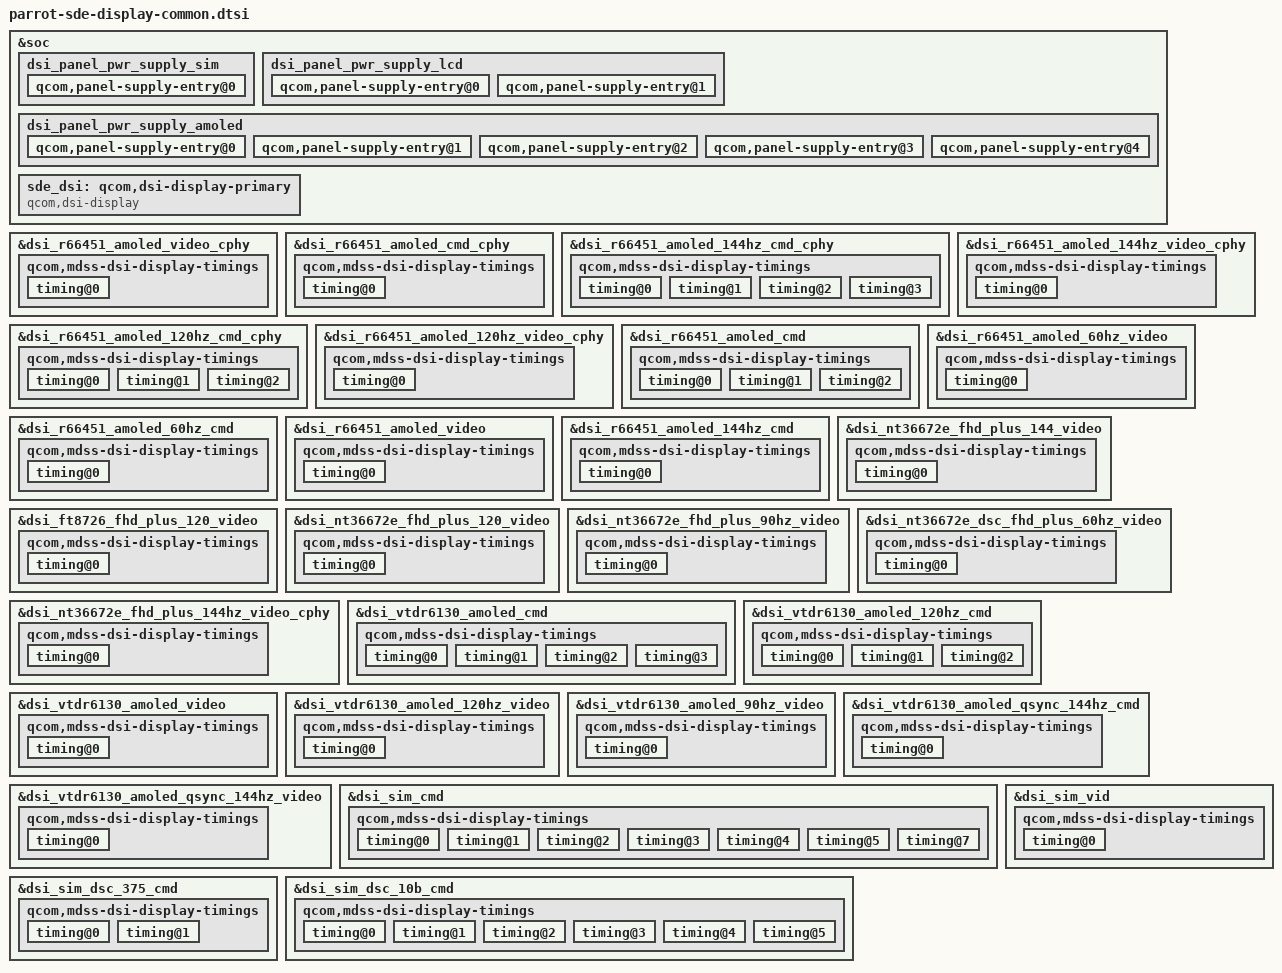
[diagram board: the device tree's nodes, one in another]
#include "dsi-panel-nt36672e-dsc-fhd-plus-60hz-video.dtsi"
#include "dsi-panel-nt36672e-fhd-plus-144-video.dtsi"
#include "dsi-panel-nt36672e-fhd-plus-120-video.dtsi"
#include "dsi-panel-nt36672e-fhd-plus-90hz-video.dtsi"
#include "dsi-panel-nt36672e-fhd-plus-144hz-video-cphy.dtsi"
#include "dsi-panel-sim-cmd.dtsi"
#include "dsi-panel-sim-video.dtsi"
#include "dsi-panel-sim-dsc-10bit-cmd.dtsi"
#include "dsi-panel-sim-dsc375-cmd.dtsi"
#include "dsi-panel-vtdr6130-dsc-fhd-plus-cmd.dtsi"
#include "dsi-panel-vtdr6130-dsc-fhd-plus-video.dtsi"
#include "dsi-panel-vtdr6130-qsync-dsc-fhd-plus-144hz-cmd.dtsi"
#include "dsi-panel-vtdr6130-qsync-dsc-fhd-plus-144hz-video.dtsi"
#include "dsi-panel-r66451-dsc-fhd-plus-cmd.dtsi"
#include "dsi-panel-r66451-dsc-fhd-plus-video.dtsi"
#include "dsi-panel-r66451-dsc-fhd-plus-144hz-cmd-cphy.dtsi"
#include "dsi-panel-r66451-dsc-fhd-plus-144hz-video-cphy.dtsi"
#include "dsi-panel-r66451-dsc-fhd-plus-120hz-cmd-cphy.dtsi"
#include "dsi-panel-r66451-dsc-fhd-plus-cmd-cphy.dtsi"
#include "dsi-panel-r66451-dsc-fhd-plus-60hz-video.dtsi"
#include "dsi-panel-r66451-dsc-fhd-plus-video-cphy.dtsi"
#include "dsi-panel-r66451-dsc-fhd-plus-144hz-cmd.dtsi"
#include "dsi-panel-r66451-dsc-fhd-plus-60hz-cmd.dtsi"
#include "dsi-r66451-amoled-120hz-video-cphy.dtsi"
#include "dsi-panel-vtdr6130-dsc-fhd-plus-120hz-cmd.dtsi"
#include "dsi-panel-vtdr6130-dsc-fhd-plus-120hz-video.dtsi"
#include "dsi-panel-ft8726-dsc-fhd-plus-video.dtsi"
#include "dsi-panel-vtdr6130-dsc-fhd-plus-90hz-video.dtsi"
#include "parrot-sde-display-pinctrl.dtsi"

&soc {
	dsi_panel_pwr_supply_sim: dsi_panel_pwr_supply_sim {
		#address-cells = <1>;
		#size-cells = <0>;

		qcom,panel-supply-entry@0 {
			reg = <0>;
			qcom,supply-name = "dummy";
			qcom,supply-min-voltage = <1800000>;
			qcom,supply-max-voltage = <1800000>;
			qcom,supply-enable-load = <200000>;
			qcom,supply-disable-load = <80>;
			qcom,supply-post-on-sleep = <20>;
		};
	};

	dsi_panel_pwr_supply_lcd: dsi_panel_pwr_supply_lcd {
		#address-cells = <1>;
		#size-cells = <0>;

		qcom,panel-supply-entry@0 {
			reg = <0>;
			qcom,supply-name = "vddio";
			qcom,supply-min-voltage = <1800000>;
			qcom,supply-max-voltage = <2000000>;
			qcom,supply-enable-load = <200000>;
			qcom,supply-disable-load = <80>;
			qcom,supply-post-on-sleep = <10>;
		};

		qcom,panel-supply-entry@1 {
			reg = <1>;
			qcom,supply-name = "avdd";
			qcom,supply-min-voltage = <4600000>;
			qcom,supply-max-voltage = <6000000>;
			qcom,supply-enable-load = <100000>;
			qcom,supply-disable-load = <100>;
			qcom,supply-post-on-sleep = <10>;
			qcom,supply-post-off-sleep = <10>;
		};
	};

	dsi_panel_pwr_supply_amoled: dsi_panel_pwr_supply_amoled {
		#address-cells = <1>;
		#size-cells = <0>;

		qcom,panel-supply-entry@0 {
			reg = <0>;
			qcom,supply-name = "vddio";
			qcom,supply-min-voltage = <1800000>;
			qcom,supply-max-voltage = <2000000>;
			qcom,supply-enable-load = <200000>;
			qcom,supply-disable-load = <80>;
			qcom,supply-post-on-sleep = <20>;
		};

		qcom,panel-supply-entry@1 {
			reg = <1>;
			qcom,supply-name = "vci";
			qcom,supply-min-voltage = <3000000>;
			qcom,supply-max-voltage = <3300000>;
			qcom,supply-enable-load = <10000>;
			qcom,supply-disable-load = <0>;
			qcom,supply-post-on-sleep = <0>;
			qcom,supply-post-off-sleep = <2>;
		};

		qcom,panel-supply-entry@2 {
			reg = <2>;
			qcom,supply-name = "lab";
			qcom,supply-min-voltage = <4600000>;
			qcom,supply-max-voltage = <6000000>;
			qcom,supply-enable-load = <0>;
			qcom,supply-disable-load = <0>;
		};

		qcom,panel-supply-entry@3 {
			reg = <3>;
			qcom,supply-name = "ibb";
			qcom,supply-min-voltage = <4600000>;
			qcom,supply-max-voltage = <6000000>;
			qcom,supply-enable-load = <0>;
			qcom,supply-disable-load = <0>;
			qcom,supply-post-on-sleep = <20>;
		};

		qcom,panel-supply-entry@4 {
			reg = <4>;
			qcom,supply-name = "extvdd";
			qcom,supply-min-voltage = <1200000>;
			qcom,supply-max-voltage = <1200000>;
			qcom,supply-enable-load = <60700>;
			qcom,supply-disable-load = <80>;
			qcom,supply-post-on-sleep = <0>;
			qcom,supply-post-off-sleep = <2>;
		};
	};

	sde_dsi: qcom,dsi-display-primary {
		compatible = "qcom,dsi-display";
		label = "primary";

		qcom,dsi-ctrl = <&mdss_dsi0>;
		qcom,dsi-phy = <&mdss_dsi_phy0>;

		pinctrl-names = "panel_active", "panel_suspend";
		pinctrl-0 = <&sde_dsi_active &sde_te_active>;
		pinctrl-1 = <&sde_dsi_suspend &sde_te_suspend>;

		qcom,platform-te-gpio = <&tlmm 99 0>;
		qcom,panel-te-source = <0>;

		qcom,mdp = <&mdss_mdp>;
		qcom,demura-panel-id = <0x0122e700 0x000000b0>;
	};
};

/* PHY TIMINGS REVISION YL with reduced margins*/
&dsi_r66451_amoled_video_cphy {
	qcom,dsi-select-clocks = "pll_byte_clk0", "pll_dsi_clk0";

	qcom,mdss-dsi-panel-status-check-mode = "reg_read";
	qcom,mdss-dsi-panel-status-command = [06 01 00 01 00 00 01 0a];
	qcom,mdss-dsi-panel-status-command-state = "dsi_lp_mode";
	qcom,mdss-dsi-panel-status-value = <0x1c>;
	qcom,mdss-dsi-panel-status-read-length = <1>;

	qcom,mdss-dsi-display-timings {
		timing@0 {
			qcom,mdss-dsi-panel-phy-timings = [00 00 00 00 12 17 04
				19 03 02 04 00 00 00];
			qcom,display-topology = <1 1 1>;
			qcom,default-topology-index = <0>;
		};
	};
};

&dsi_r66451_amoled_cmd_cphy {
	qcom,dsi-select-clocks = "pll_byte_clk0", "pll_dsi_clk0";

	qcom,esd-check-enabled;
	qcom,mdss-dsi-panel-status-check-mode = "reg_read";
	qcom,mdss-dsi-panel-status-command = [06 01 00 01 00 00 01 0a];
	qcom,mdss-dsi-panel-status-command-state = "dsi_lp_mode";
	qcom,mdss-dsi-panel-status-value = <0x1c>;
	qcom,mdss-dsi-panel-status-read-length = <1>;

	qcom,mdss-dsi-display-timings {
		timing@0 {
			qcom,mdss-dsi-panel-phy-timings = [00 00 00 00 10 13 03
				19 02 02 04 00 00 00];
			qcom,display-topology = <1 1 1>;
			qcom,default-topology-index = <0>;
		};
	};
};

&dsi_r66451_amoled_144hz_cmd_cphy {
	qcom,dsi-select-clocks = "pll_byte_clk0", "pll_dsi_clk0";

	qcom,esd-check-enabled;
	qcom,mdss-dsi-panel-status-check-mode = "reg_read";
	qcom,mdss-dsi-panel-status-command = [06 01 00 01 00 00 01 0a];
	qcom,mdss-dsi-panel-status-command-state = "dsi_lp_mode";
	qcom,mdss-dsi-panel-status-value = <0x1c>;
	qcom,mdss-dsi-panel-status-read-length = <1>;

	qcom,mdss-dsi-display-timings {
		timing@0 {
			qcom,mdss-dsi-panel-phy-timings = [00 00 00 00 15 1f 06
				19 07 02 04 00 00 00];
			qcom,display-topology = <1 1 1>;
			qcom,default-topology-index = <0>;
		};

		timing@1 {
			qcom,mdss-dsi-panel-phy-timings = [00 00 00 00 10 13 03
				19 02 02 04 00 00 00];
			qcom,display-topology = <1 1 1>;
			qcom,default-topology-index = <0>;
		};

		timing@2 {
			qcom,mdss-dsi-panel-phy-timings = [00 00 00 00 14 1b 05
				19 06 02 04 00 00 00];
			qcom,display-topology = <1 1 1>;
			qcom,default-topology-index = <0>;
		};

		timing@3 {
			qcom,mdss-dsi-panel-phy-timings = [00 00 00 00 12 17 04
				19 03 02 04 00 00 00];
			qcom,display-topology = <1 1 1>;
			qcom,default-topology-index = <0>;
		};
	};
};

&dsi_r66451_amoled_144hz_video_cphy {
	qcom,dsi-select-clocks = "pll_byte_clk0", "pll_dsi_clk0";

	qcom,esd-check-enabled;
	qcom,mdss-dsi-panel-status-check-mode = "reg_read";
	qcom,mdss-dsi-panel-status-command = [06 01 00 01 00 00 01 0a];
	qcom,mdss-dsi-panel-status-command-state = "dsi_lp_mode";
	qcom,mdss-dsi-panel-status-value = <0x1c>;
	qcom,mdss-dsi-panel-status-read-length = <1>;

	qcom,mdss-dsi-display-timings {
	timing@0 {
			qcom,mdss-dsi-panel-phy-timings = [00 00 00 00 15 1f 06
				19 07 02 04 00 00 00];
			qcom,display-topology = <1 1 1>;
			qcom,default-topology-index = <0>;
		};
	};
};

&dsi_r66451_amoled_120hz_cmd_cphy {
	qcom,dsi-select-clocks = "pll_byte_clk0", "pll_dsi_clk0";

	qcom,esd-check-enabled;
	qcom,mdss-dsi-panel-status-check-mode = "reg_read";
	qcom,mdss-dsi-panel-status-command = [06 01 00 01 00 00 01 0a];
	qcom,mdss-dsi-panel-status-command-state = "dsi_lp_mode";
	qcom,mdss-dsi-panel-status-value = <0x1c>;
	qcom,mdss-dsi-panel-status-read-length = <1>;

	qcom,mdss-dsi-display-timings {
		timing@0 {
			qcom,mdss-dsi-panel-phy-timings = [00 00 00 00 10 13 03
				19 02 02 04 00 00 00];
			qcom,display-topology = <1 1 1>;
			qcom,default-topology-index = <0>;
		};

		timing@1 {
			qcom,mdss-dsi-panel-phy-timings = [00 00 00 00 12 17 04
				19 03 02 04 00 00 00];
			qcom,display-topology = <1 1 1>;
			qcom,default-topology-index = <0>;
		};

		timing@2 {
			qcom,mdss-dsi-panel-phy-timings = [00 00 00 00 14 1b 05
				19 06 02 04 00 00 00];
			qcom,display-topology = <1 1 1>;
			qcom,default-topology-index = <0>;
		};
	};
};

&dsi_r66451_amoled_120hz_video_cphy {
	qcom,dsi-select-clocks = "pll_byte_clk0", "pll_dsi_clk0";

	qcom,esd-check-enabled;
	qcom,mdss-dsi-panel-status-check-mode = "reg_read";
	qcom,mdss-dsi-panel-status-command = [06 01 00 01 00 00 01 0a];
	qcom,mdss-dsi-panel-status-command-state = "dsi_lp_mode";
	qcom,mdss-dsi-panel-status-value = <0x1c>;
	qcom,mdss-dsi-panel-status-read-length = <1>;

	qcom,mdss-dsi-display-timings {
		timing@0 {
			qcom,mdss-dsi-panel-phy-timings = [00 00 00 00 14 1b 05
				19 06 02 04 00 00 00];
			qcom,display-topology = <1 1 1>;
			qcom,default-topology-index = <0>;
		};
	};
};

&dsi_r66451_amoled_cmd {
	qcom,dsi-select-clocks = "pll_byte_clk0", "pll_dsi_clk0";

	qcom,esd-check-enabled;
	qcom,mdss-dsi-panel-status-check-mode = "reg_read";
	qcom,mdss-dsi-panel-status-command = [06 01 00 01 00 00 01 0a];
	qcom,mdss-dsi-panel-status-command-state = "dsi_lp_mode";
	qcom,mdss-dsi-panel-status-value = <0x1c>;
	qcom,mdss-dsi-panel-status-read-length = <1>;

	qcom,mdss-dsi-display-timings {
		timing@0 {
			qcom,mdss-dsi-panel-phy-timings = [00 10 04 04 12 1e 04
				04 03 02 04 00 0e 09];
			qcom,display-topology = <1 1 1>;
			qcom,default-topology-index = <0>;
		};

		timing@1 {
			qcom,mdss-dsi-panel-phy-timings = [00 16 06 05 14 1f 06
				06 06 02 04 00 14 0b];
			qcom,display-topology = <1 1 1>;
			qcom,default-topology-index = <0>;
		};

		timing@2 {
			qcom,mdss-dsi-panel-phy-timings = [00 1c 08 07 17 22 07
				07 08 02 04 00 19 0c];
			qcom,display-topology = <1 1 1>;
			qcom,default-topology-index = <0>;
		};
	};
};

&dsi_r66451_amoled_60hz_video {
	qcom,dsi-select-clocks = "pll_byte_clk0", "pll_dsi_clk0";

	qcom,esd-check-enabled;
	qcom,mdss-dsi-panel-status-check-mode = "reg_read";
	qcom,mdss-dsi-panel-status-command = [06 01 00 01 00 00 01 0a];
	qcom,mdss-dsi-panel-status-command-state = "dsi_lp_mode";
	qcom,mdss-dsi-panel-status-value = <0x1c>;
	qcom,mdss-dsi-panel-status-read-length = <1>;

	qcom,mdss-dsi-display-timings {
		timing@0{
			qcom,mdss-dsi-panel-phy-timings = [00 10 04 04 12 1e 04
				04 03 02 04 00 0e 09];
			qcom,display-topology = <1 1 1>;
			qcom,default-topology-index = <0>;
		};
	};
};

&dsi_r66451_amoled_60hz_cmd {
	qcom,dsi-select-clocks = "pll_byte_clk0", "pll_dsi_clk0";

	qcom,esd-check-enabled;
	qcom,mdss-dsi-panel-status-check-mode = "reg_read";
	qcom,mdss-dsi-panel-status-command = [06 01 00 01 00 00 01 0a];
	qcom,mdss-dsi-panel-status-command-state = "dsi_lp_mode";
	qcom,mdss-dsi-panel-status-value = <0x1c>;
	qcom,mdss-dsi-panel-status-read-length = <1>;

	qcom,mdss-dsi-display-timings {
		timing@0 {
			qcom,mdss-dsi-panel-phy-timings = [00 10 04 04 12 1E 04
				04 03 02 04 00 0E 09];
			qcom,display-topology = <1 1 1>;
			qcom,default-topology-index = <0>;
		};
	};
};

&dsi_r66451_amoled_video {
	qcom,dsi-select-clocks = "pll_byte_clk0", "pll_dsi_clk0";

	qcom,esd-check-enabled;
	qcom,mdss-dsi-panel-status-check-mode = "reg_read";
	qcom,mdss-dsi-panel-status-command = [06 01 00 01 00 00 01 0a];
	qcom,mdss-dsi-panel-status-command-state = "dsi_lp_mode";
	qcom,mdss-dsi-panel-status-value = <0x1c>;
	qcom,mdss-dsi-panel-status-read-length = <1>;

	qcom,mdss-dsi-display-timings {
		timing@0 {
			qcom,mdss-dsi-panel-phy-timings = [00 1c 08 07 17 22 07
				07 08 02 04 00 19 0c];
			qcom,display-topology = <1 1 1>;
			qcom,default-topology-index = <0>;
		};
	};
};

&dsi_r66451_amoled_144hz_cmd {
	qcom,dsi-select-clocks = "pll_byte_clk0", "pll_dsi_clk0";

	qcom,esd-check-enabled;
	qcom,mdss-dsi-panel-status-check-mode = "reg_read";
	qcom,mdss-dsi-panel-status-command = [06 01 00 01 00 00 01 0a];
	qcom,mdss-dsi-panel-status-command-state = "dsi_lp_mode";
	qcom,mdss-dsi-panel-status-value = <0x1c>;
	qcom,mdss-dsi-panel-status-read-length = <1>;

	qcom,mdss-dsi-display-timings {
		timing@0 {
			qcom,mdss-dsi-panel-phy-timings = [00 22 09 09 19 23 09
				09 09 02 04 00 1d 0e];
			qcom,display-topology = <1 1 1>;
			qcom,default-topology-index = <0>;
		};
	};
};

&dsi_nt36672e_fhd_plus_144_video{
	qcom,dsi-select-clocks = "pll_byte_clk0", "pll_dsi_clk0";

	qcom,qsync-enable;
	qcom,mdss-dsi-qsync-min-refresh-rate = <48>;

	qcom,dsi-supported-dfps-list = <144 120 60 48>;
	qcom,mdss-dsi-pan-enable-dynamic-fps;
	qcom,mdss-dsi-pan-fps-update = "dfps_immediate_porch_mode_vfp";

	qcom,dsi-dyn-clk-enable;
	qcom,dsi-dyn-clk-type = "constant-fps-adjust-vfp";

	qcom,esd-check-enabled;
	qcom,mdss-dsi-panel-status-check-mode = "reg_read";
	qcom,mdss-dsi-panel-status-command = [06 01 00 01 00 00 01 0a];
	qcom,mdss-dsi-panel-status-command-state = "dsi_lp_mode";
	qcom,mdss-dsi-panel-status-value = <0x9c>;
	qcom,mdss-dsi-panel-status-read-length = <1>;

	qcom,mdss-dsi-display-timings {
		timing@0 {
			qcom,mdss-dsi-panel-phy-timings = [00 20 08 08 18 23 08
				08 08 02 04 00 1b 0d];
			qcom,display-topology = <1 1 1>;
			qcom,default-topology-index = <0>;
			qcom,dsi-dyn-clk-list = <957616128 950966016 954291072>;
		};
	};
};

&dsi_ft8726_fhd_plus_120_video {
	qcom,dsi-select-clocks = "pll_byte_clk0", "pll_dsi_clk0";

	qcom,esd-check-enabled;
	qcom,mdss-dsi-panel-status-check-mode = "reg_read";
	qcom,mdss-dsi-panel-status-command = [06 01 00 01 00 00 01 0a];
	qcom,mdss-dsi-panel-status-command-state = "dsi_lp_mode";
	qcom,mdss-dsi-panel-status-value = <0x9c>;
	qcom,mdss-dsi-panel-status-read-length = <1>;

	qcom,mdss-dsi-display-timings {
	timing@0 {
			qcom,mdss-dsi-panel-phy-timings = [00 1b 07 06 16 21 07
				07 07 02 04 00 17 0c];
			qcom,display-topology = <1 1 1>;
			qcom,default-topology-index = <0>;
		};
	};
};

&dsi_nt36672e_fhd_plus_120_video {
	qcom,dsi-select-clocks = "pll_byte_clk0", "pll_dsi_clk0";

	qcom,qsync-enable;
	qcom,mdss-dsi-qsync-min-refresh-rate = <48>;

	qcom,dsi-supported-dfps-list = <120 60 48>;
	qcom,mdss-dsi-pan-enable-dynamic-fps;
	qcom,mdss-dsi-pan-fps-update = "dfps_immediate_porch_mode_vfp";

	qcom,dsi-dyn-clk-enable;
	qcom,dsi-dyn-clk-type = "constant-fps-adjust-vfp";

	qcom,esd-check-enabled;
	qcom,mdss-dsi-panel-status-check-mode = "reg_read";
	qcom,mdss-dsi-panel-status-command = [06 01 00 01 00 00 01 0a];
	qcom,mdss-dsi-panel-status-command-state = "dsi_lp_mode";
	qcom,mdss-dsi-panel-status-value = <0x9c>;
	qcom,mdss-dsi-panel-status-read-length = <1>;

	qcom,mdss-dsi-display-timings {
		timing@0 {
			qcom,mdss-dsi-panel-phy-timings = [00 1e 08 07 18 22 08
				08 08 02 04 00 1a 0d];
			qcom,display-topology = <1 1 1>;
			qcom,default-topology-index = <0>;
			qcom,dsi-dyn-clk-list = <912015360 904415232 908215296>;
		};
	};
};

&dsi_nt36672e_fhd_plus_90hz_video{
	qcom,dsi-select-clocks = "pll_byte_clk0", "pll_dsi_clk0";

	qcom,esd-check-enabled;
	qcom,mdss-dsi-panel-status-check-mode = "reg_read";
	qcom,mdss-dsi-panel-status-command = [06 01 00 01 00 00 01 0a];
	qcom,mdss-dsi-panel-status-command-state = "dsi_lp_mode";
	qcom,mdss-dsi-panel-status-value = <0x9c>;
	qcom,mdss-dsi-panel-status-read-length = <1>;

	qcom,mdss-dsi-display-timings {
		timing@0 {
			qcom,mdss-dsi-panel-phy-timings = [00 18 06 06 15 20 06
				06 07 02 04 00 15 0b];
			qcom,display-topology = <1 1 1>;
			qcom,default-topology-index = <0>;
		};
	};
};

&dsi_nt36672e_dsc_fhd_plus_60hz_video{
	qcom,dsi-select-clocks = "pll_byte_clk0", "pll_dsi_clk0";

	qcom,esd-check-enabled;
	qcom,mdss-dsi-panel-status-check-mode = "reg_read";
	qcom,mdss-dsi-panel-status-command = [06 01 00 01 00 00 01 0a];
	qcom,mdss-dsi-panel-status-command-state = "dsi_lp_mode";
	qcom,mdss-dsi-panel-status-value = <0x9c>;
	qcom,mdss-dsi-panel-status-read-length = <1>;

	qcom,mdss-dsi-display-timings {
		timing@0 {
			qcom,mdss-dsi-panel-phy-timings = [00 11 04 04 12 1e 04
				04 03 02 04 00 0f 09];
			qcom,display-topology = <1 1 1>;
			qcom,default-topology-index = <0>;
		};
	};
};

&dsi_nt36672e_fhd_plus_144hz_video_cphy{
	qcom,dsi-select-clocks = "pll_byte_clk0", "pll_dsi_clk0";

	qcom,esd-check-enabled;
	qcom,mdss-dsi-panel-status-check-mode = "reg_read";
	qcom,mdss-dsi-panel-status-command = [06 01 00 01 00 00 01 0a];
	qcom,mdss-dsi-panel-status-command-state = "dsi_lp_mode";
	qcom,mdss-dsi-panel-status-value = <0x9c>;
	qcom,mdss-dsi-panel-status-read-length = <1>;

	qcom,mdss-dsi-display-timings {
		timing@0 {
			qcom,mdss-dsi-panel-phy-timings = [00 00 00 00 16 1f 06
				19 07 02 04 00 00 00];
			qcom,display-topology = <1 1 1>;
			qcom,default-topology-index = <0>;
		};
	};
};

&dsi_vtdr6130_amoled_cmd {
	qcom,dsi-select-clocks = "pll_byte_clk0", "pll_dsi_clk0";

	qcom,dsi-dyn-clk-enable;

	qcom,esd-check-enabled;
	qcom,mdss-dsi-panel-status-check-mode = "reg_read";
	qcom,mdss-dsi-panel-status-command = [06 01 00 01 00 00 01 0a];
	qcom,mdss-dsi-panel-status-command-state = "dsi_lp_mode";
	qcom,mdss-dsi-panel-status-value = <0x9c>;
	qcom,mdss-dsi-panel-status-read-length = <1>;

	qcom,mdss-dsi-display-timings {
		timing@0 {
			qcom,mdss-dsi-panel-phy-timings = [00 1c 08 07 17 22 07
				07 08 02 04 00 19 0c];
			qcom,display-topology = <1 1 1>;
			qcom,default-topology-index = <0>;
			qcom,dsi-dyn-clk-list = <847480320 850422960 853365600>;
		};
		timing@1 {
			qcom,mdss-dsi-panel-phy-timings = [00 1c 08 07 17 22 07
				07 08 02 04 00 19 0c];
			qcom,display-topology = <1 1 1>;
			qcom,default-topology-index = <0>;
			qcom,dsi-dyn-clk-list = <847480320 850422960 853365600>;
		};
		timing@2 {
			qcom,mdss-dsi-panel-phy-timings = [00 1c 08 07 17 22 07
				07 08 02 04 00 19 0c];
			qcom,display-topology = <1 1 1>;
			qcom,default-topology-index = <0>;
			qcom,dsi-dyn-clk-list = <847480320 850422960 853365600>;
		};
		timing@3 {
			qcom,mdss-dsi-panel-phy-timings = [00 1c 08 07 17 22 07
				07 08 02 04 00 19 0c];
			qcom,display-topology = <1 1 1>;
			qcom,default-topology-index = <0>;
			qcom,dsi-dyn-clk-list = <847480320 850422960 853365600>;
		};
	};
};

&dsi_vtdr6130_amoled_120hz_cmd {
	qcom,dsi-select-clocks = "pll_byte_clk0", "pll_dsi_clk0";

	qcom,esd-check-enabled;
	qcom,mdss-dsi-panel-status-check-mode = "reg_read";
	qcom,mdss-dsi-panel-status-command = [06 01 00 01 00 00 01 0a];
	qcom,mdss-dsi-panel-status-command-state = "dsi_lp_mode";
	qcom,mdss-dsi-panel-status-value = <0x9c>;
	qcom,mdss-dsi-panel-status-read-length = <1>;

	qcom,mdss-dsi-display-timings {
		timing@0 {
			qcom,mdss-dsi-panel-phy-timings = [00 19 06 06 15 20 07
				06 07 02 04 00 16 0b];
			qcom,display-topology = <1 1 1>;
			qcom,default-topology-index = <0>;
		};
		timing@1 {
			qcom,mdss-dsi-panel-phy-timings = [00 19 06 06 15 20 07
				06 07 02 04 00 16 0b];
			qcom,display-topology = <1 1 1>;
			qcom,default-topology-index = <0>;
		};
		timing@2 {
			qcom,mdss-dsi-panel-phy-timings = [00 19 06 06 15 20 07
				06 07 02 04 00 16 0b];
			qcom,display-topology = <1 1 1>;
			qcom,default-topology-index = <0>;
		};
	};
};

&dsi_vtdr6130_amoled_video {
	qcom,dsi-select-clocks = "pll_byte_clk0", "pll_dsi_clk0";

	qcom,dsi-supported-dfps-list = <144 120 90 60>;
	qcom,mdss-dsi-pan-enable-dynamic-fps;
	qcom,mdss-dsi-pan-fps-update = "dfps_immediate_porch_mode_vfp";

	qcom,dsi-dyn-clk-enable;
	qcom,dsi-dyn-clk-type = "constant-fps-adjust-hfp";

	qcom,esd-check-enabled;
	qcom,mdss-dsi-panel-status-check-mode = "reg_read";
	qcom,mdss-dsi-panel-status-command = [06 01 00 01 00 00 01 0a];
	qcom,mdss-dsi-panel-status-command-state = "dsi_lp_mode";
	qcom,mdss-dsi-panel-status-value = <0x9c>;
	qcom,mdss-dsi-panel-status-read-length = <1>;

	qcom,mdss-dsi-display-timings {
		timing@0 {
			qcom,mdss-dsi-panel-phy-timings = [00 1c 08 07 17 22 07
				07 08 02 04 00 19 0c];
			qcom,display-topology = <1 1 1>;
			qcom,default-topology-index = <0>;
			qcom,dsi-dyn-clk-list = <847480320 844537680 841595040>;
		};
	};
};

&dsi_vtdr6130_amoled_120hz_video {
	qcom,dsi-select-clocks = "pll_byte_clk0", "pll_dsi_clk0";

	qcom,dsi-supported-dfps-list = <120 90 60>;
	qcom,mdss-dsi-pan-enable-dynamic-fps;
	qcom,mdss-dsi-pan-fps-update = "dfps_immediate_porch_mode_vfp";

	qcom,esd-check-enabled;
	qcom,mdss-dsi-panel-status-check-mode = "reg_read";
	qcom,mdss-dsi-panel-status-command = [06 01 00 01 00 00 01 0a];
	qcom,mdss-dsi-panel-status-command-state = "dsi_lp_mode";
	qcom,mdss-dsi-panel-status-value = <0x9c>;
	qcom,mdss-dsi-panel-status-read-length = <1>;

	qcom,mdss-dsi-display-timings {
		timing@0 {
			qcom,mdss-dsi-panel-phy-timings = [00 19 06 06 15 14 07
				06 07 02 04 00 16 0b];
			qcom,display-topology = <1 1 1>;
			qcom,default-topology-index = <0>;
		};
	};
};

&dsi_vtdr6130_amoled_90hz_video {
	qcom,dsi-select-clocks = "pll_byte_clk0", "pll_dsi_clk0";

	qcom,esd-check-enabled;
	qcom,mdss-dsi-panel-status-check-mode = "reg_read";
	qcom,mdss-dsi-panel-status-command = [06 01 00 01 00 00 01 0a];
	qcom,mdss-dsi-panel-status-command-state = "dsi_lp_mode";
	qcom,mdss-dsi-panel-status-value = <0x9c>;
	qcom,mdss-dsi-panel-status-read-length = <1>;

	qcom,mdss-dsi-display-timings {
		timing@0 {
			qcom,mdss-dsi-panel-phy-timings = [00 13 05 04 13 1e 05
				05 06 02 04 00 12 0a];
			qcom,display-topology = <1 1 1>;
			qcom,default-topology-index = <0>;
		};
	};
};

&dsi_vtdr6130_amoled_qsync_144hz_cmd {
	qcom,dsi-select-clocks = "pll_byte_clk0", "pll_dsi_clk0";

	qcom,esd-check-enabled;
	qcom,mdss-dsi-panel-status-check-mode = "reg_read";
	qcom,mdss-dsi-panel-status-command = [06 01 00 01 00 00 01 0a];
	qcom,mdss-dsi-panel-status-command-state = "dsi_lp_mode";
	qcom,mdss-dsi-panel-status-value = <0x9c>;
	qcom,mdss-dsi-panel-status-read-length = <1>;

	qcom,mdss-dsi-display-timings {
		timing@0 {
			qcom,mdss-dsi-panel-phy-timings = [00 1c 08 07 17 22 07
				07 08 02 04 00 19 0c];
			qcom,display-topology = <1 1 1>;
			qcom,default-topology-index = <0>;
		};
	};
};

&dsi_vtdr6130_amoled_qsync_144hz_video {
	qcom,dsi-select-clocks = "pll_byte_clk0", "pll_dsi_clk0";

	qcom,esd-check-enabled;
	qcom,mdss-dsi-panel-status-check-mode = "reg_read";
	qcom,mdss-dsi-panel-status-command = [06 01 00 01 00 00 01 0a];
	qcom,mdss-dsi-panel-status-command-state = "dsi_lp_mode";
	qcom,mdss-dsi-panel-status-value = <0x9c>;
	qcom,mdss-dsi-panel-status-read-length = <1>;

	qcom,mdss-dsi-display-timings {
		timing@0 {
			qcom,mdss-dsi-panel-phy-timings = [00 1c 08 07 17 22 07
				07 08 02 04 00 19 0c];
			qcom,display-topology = <1 1 1>;
			qcom,default-topology-index = <0>;
		};
	};
};

&dsi_sim_cmd {
	qcom,dsi-select-clocks = "pll_byte_clk0", "pll_dsi_clk0";

	qcom,poms-align-panel-vsync;

	qcom,mdss-dsi-display-timings {
		timing@0 { /* WQHD 60FPS cmd-vid mode*/
			qcom,mdss-dsi-panel-phy-timings = [00 19 06 06 15 20 07
				06 07 02 04 00 16 0b];
			qcom,display-topology = <1 1 1>,
						<2 2 1>;
			qcom,default-topology-index = <0>;
		};

		timing@1 { /* WQHD 60FPS vid mode*/
			qcom,mdss-dsi-panel-phy-timings = [00 19 06 06 15 20 07
				06 07 02 04 00 16 0b];
			qcom,display-topology = <1 1 1>,
						<2 2 1>;
			qcom,default-topology-index = <0>;
		};

		timing@2 { /* FHD+ 60FPS cmd mode*/
			qcom,mdss-dsi-panel-phy-timings = [00 1d 08 07 17 22 08
				08 08 02 04 00 19 0d];
			qcom,display-topology = <1 1 1>,
						<2 2 1>;
			qcom,default-topology-index = <0>;
		};

		timing@3 { /* HD 60FPS cmd mode */
			qcom,mdss-dsi-panel-phy-timings = [00 17 05 05 14 1f 06
				06 06 02 04 00 14 0b];
			qcom,display-topology = <1 1 1>,
						<2 2 1>;
			qcom,default-topology-index = <0>;
		};

		timing@4 { /* FHD+ 90FPS cmd mode*/
			qcom,mdss-dsi-panel-phy-timings = [00 2b 0b 0b 1c 27 0b
				0c 0b 02 04 00 23 10];
			qcom,display-topology = <1 1 1>,
						<2 2 1>;
			qcom,default-topology-index = <0>;
		};

		timing@5 { /* FHD+ 180 FPS cmd mode*/
			qcom,mdss-dsi-panel-phy-timings = [00 54 16 16 23 1e 15
				17 13 02 04 00 40 1a];
			qcom,display-topology = <1 1 1>;
			qcom,default-topology-index = <0>;
		};

		/delete-node/ timing@6; /* FHD+ 240 FPS cmd mode*/

		timing@7 { /* FHD+ 120FPS cmd mode*/
			cell-index = <6>;
			qcom,mdss-dsi-panel-phy-timings = [00 3b 0f 0f 18 15 0f
				0f 0d 02 04 00 2d 12];
			qcom,display-topology = <1 1 1>,
						<2 2 1>;
			qcom,default-topology-index = <0>;
		};
	};
};

&dsi_sim_vid {
	qcom,dsi-select-clocks = "pll_byte_clk0", "pll_dsi_clk0";

	qcom,mdss-dsi-display-timings {
		timing@0 {
			qcom,mdss-dsi-panel-phy-timings = [01 09 01 01 0e 1b 01
				01 02 02 04 00 08 06];
			qcom,display-topology = <1 0 1>,
						<2 0 1>;
			qcom,default-topology-index = <0>;
		};
	};
};

&dsi_sim_dsc_375_cmd {
	qcom,dsi-select-clocks = "pll_byte_clk0", "pll_dsi_clk0";
	qcom,mdss-dsi-display-timings {
		timing@0 { /* 1080p */
			qcom,mdss-dsi-panel-phy-timings = [00 15 05 05 14 1f 05
				05 06 02 04 00 13 0a];
			qcom,display-topology = <1 1 1>;
			qcom,default-topology-index = <0>;
		};

		timing@1 { /* qhd */
			qcom,mdss-dsi-panel-phy-timings = [00 0c 02 02 10 1c 03
				03 02 02 04 00 0b 08];
			qcom,display-topology = <1 1 1>,
						<2 2 1>, /* dsc merge */
						<2 1 1>; /* 3d mux */
			qcom,default-topology-index = <0>;
		};
	};
};

&dsi_sim_dsc_10b_cmd {
	qcom,dsi-select-clocks = "pll_byte_clk0", "pll_dsi_clk0";
	qcom,mdss-dsi-display-timings {
		timing@0 { /* QHD 60fps */
			qcom,mdss-dsi-panel-phy-timings = [00 15 05 05 14 1f 05
				05 06 02 04 00 13 0a];
			qcom,display-topology = <1 1 1>;
			qcom,default-topology-index = <0>;
		};

		timing@1 { /* FHD+ 60fps cmd mode */
			qcom,mdss-dsi-panel-phy-timings = [00 0d 03 03 10 1d 03
				03 02 02 04 00 0c 08];
			qcom,display-topology = <1 1 1>,
						<2 2 1>, /* dsc merge */
						<2 1 1>; /* 3d mux */
			qcom,default-topology-index = <0>;
		};

		timing@2 { /* QHD 90fps */
			qcom,mdss-dsi-panel-phy-timings = [00 1d 08 07 17 22 08
				08 08 02 04 00 19 0d];
			qcom,display-topology = <1 1 1>;
			qcom,default-topology-index = <0>;
		};

		timing@3 { /* FHD+ 180FPS cmd mode*/
			qcom,mdss-dsi-panel-phy-timings = [00 1f 08 07 18 16 08
				08 08 02 04 00 1a 0d];
			qcom,display-topology = <1 1 1>;
			qcom,default-topology-index = <0>;
		};

		timing@4 { /* FHD+ 240FPS cmd mode*/
			qcom,mdss-dsi-panel-phy-timings = [00 28 0a 0b 1b 1a 0a
				0b 0a 02 04 00 21 0f];
			qcom,display-topology = <1 1 1>;
			qcom,default-topology-index = <0>;
		};

		timing@5 { /* FHD+ 120FPS cmd mode*/
			qcom,mdss-dsi-panel-phy-timings = [00 16 05 05 14 13 06
				06 06 02 04 00 13 0b];
			qcom,display-topology = <1 1 1>;
			qcom,default-topology-index = <0>;
		};
	};
};
